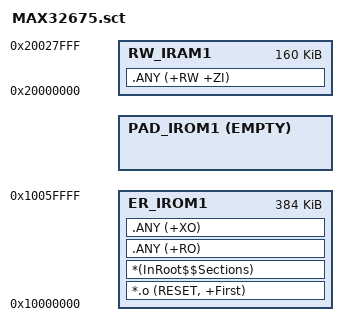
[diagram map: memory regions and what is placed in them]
LR_IROM1 0x10000000 0x60000
{
  ER_IROM1 0x10000000 0x60000
  {
    *.o (RESET, +First)
    *(InRoot$$Sections)
    .ANY (+RO)
    .ANY (+XO)
  }
  
  PAD_IROM1 +0 ALIGN 16 EMPTY 0
  {
    ; This empty region forces the previous region to 
    ;  always be a multiple of 16 bytes.  This is 
    ;  necessary for devices where flash ECC is enabled.
  }

  RW_IRAM1 0x20000000 0x00028000  
  {
    .ANY (+RW +ZI)
  }
}

